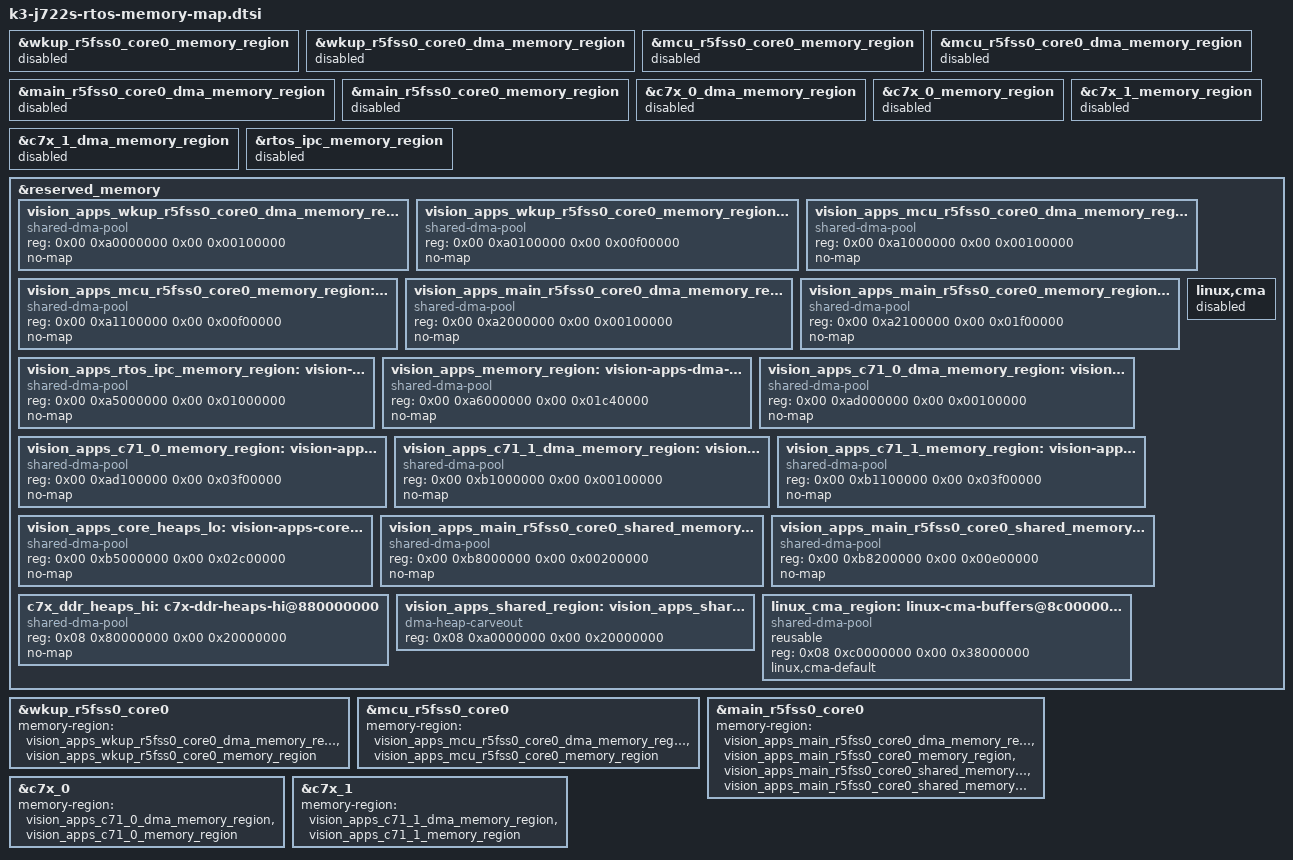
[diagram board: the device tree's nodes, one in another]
// SPDX-License-Identifier: GPL-2.0
/*
 * Vision-apps: device-tree overlay
 *
 * Copyright (C) 2019 Texas Instruments Incorporated - http://www.ti.com/
 */

#include <dt-bindings/soc/ti,sci_pm_domain.h>

&wkup_r5fss0_core0_memory_region {
	status = "disabled";
};

&wkup_r5fss0_core0_dma_memory_region {
	status = "disabled";
};

&mcu_r5fss0_core0_memory_region {
	status = "disabled";
};

&mcu_r5fss0_core0_dma_memory_region {
	status = "disabled";
};

&main_r5fss0_core0_dma_memory_region {
	status = "disabled";
};

&main_r5fss0_core0_memory_region {
	status = "disabled";
};

&c7x_0_dma_memory_region {
	status = "disabled";
};

&c7x_0_memory_region {
	status = "disabled";
};

&c7x_1_dma_memory_region {
	status = "disabled";
};

&c7x_1_memory_region {
	status = "disabled";
};

&rtos_ipc_memory_region {
	status = "disabled";
};

&reserved_memory {
	#address-cells = <2>;
	#size-cells = <2>;

	vision_apps_wkup_r5fss0_core0_dma_memory_region: vision-apps-r5f-dma-memory@a0000000 {
		compatible = "shared-dma-pool";
		reg = <0x00 0xa0000000 0x00 0x00100000>;
		no-map;
	};
	vision_apps_wkup_r5fss0_core0_memory_region: vision-apps-r5f-memory@a0100000 {
		compatible = "shared-dma-pool";
		reg = <0x00 0xa0100000 0x00 0x00f00000>;
		no-map;
	};
	vision_apps_mcu_r5fss0_core0_dma_memory_region: vision-apps-r5f-dma-memory@a1000000 {
		compatible = "shared-dma-pool";
		reg = <0x00 0xa1000000 0x00 0x00100000>;
		no-map;
	};
	vision_apps_mcu_r5fss0_core0_memory_region: vision-apps-r5f-memory@a1100000 {
		compatible = "shared-dma-pool";
		reg = <0x00 0xa1100000 0x00 0x00f00000>;
		no-map;
	};
	vision_apps_main_r5fss0_core0_dma_memory_region: vision-apps-r5f-dma-memory@a2000000 {
		compatible = "shared-dma-pool";
		reg = <0x00 0xa2000000 0x00 0x00100000>;
		no-map;
	};
	vision_apps_main_r5fss0_core0_memory_region: vision-apps-r5f-memory@a2100000 {
		compatible = "shared-dma-pool";
		reg = <0x00 0xa2100000 0x00 0x01f00000>;
		no-map;
	};
	vision_apps_rtos_ipc_memory_region: vision-apps-rtos-ipc-memory-region@a5000000 {
		compatible = "shared-dma-pool";
		reg = <0x00 0xa5000000 0x00 0x01000000>;
		no-map;
	};
	vision_apps_memory_region: vision-apps-dma-memory@a6000000 {
		compatible = "shared-dma-pool";
		reg = <0x00 0xa6000000 0x00 0x01c40000>;
		no-map;
	};
	vision_apps_c71_0_dma_memory_region: vision-apps-c71-dma-memory@ad000000 {
		compatible = "shared-dma-pool";
		reg = <0x00 0xad000000 0x00 0x00100000>;
		no-map;
	};
	vision_apps_c71_0_memory_region: vision-apps-c71_0-memory@ad100000 {
		compatible = "shared-dma-pool";
		reg = <0x00 0xad100000 0x00 0x03f00000>;
		no-map;
	};
	vision_apps_c71_1_dma_memory_region: vision-apps-c71_1-dma-memory@b1000000 {
		compatible = "shared-dma-pool";
		reg = <0x00 0xb1000000 0x00 0x00100000>;
		no-map;
	};
	vision_apps_c71_1_memory_region: vision-apps-c71_1-memory@b1100000 {
		compatible = "shared-dma-pool";
		reg = <0x00 0xb1100000 0x00 0x03f00000>;
		no-map;
	};
	vision_apps_core_heaps_lo: vision-apps-core-heap-memory-lo@b5000000 {
		compatible = "shared-dma-pool";
		reg = <0x00 0xb5000000 0x00 0x02c00000>;
		no-map;
	};
	vision_apps_main_r5fss0_core0_shared_memory_queue_region: vision-apps-r5f-virtual-eth-queues@b8000000 {
		compatible = "shared-dma-pool";
		reg = <0x00 0xb8000000 0x00 0x00200000>;
		no-map;
	};
	vision_apps_main_r5fss0_core0_shared_memory_bufpool_region: vision-apps-r5f-virtual-eth-buffers@b8200000 {
		compatible = "shared-dma-pool";
		reg = <0x00 0xb8200000 0x00 0x00e00000>;
		no-map;
	};
	c7x_ddr_heaps_hi: c7x-ddr-heaps-hi@880000000 {
		compatible = "shared-dma-pool";
		reg = <0x08 0x80000000 0x00 0x20000000>;
		no-map;
	};
	vision_apps_shared_region: vision_apps_shared-memories {
		compatible = "dma-heap-carveout";
		reg = <0x08 0xa0000000 0x00 0x20000000>;
	};
	linux,cma {
		status = "disabled";
	};
	linux_cma_region: linux-cma-buffers@8c0000000 {
		compatible = "shared-dma-pool";
		reusable;
		reg = <0x08 0xc0000000 0x00 0x38000000>;
		linux,cma-default;
	};
};

&wkup_r5fss0_core0 {
	memory-region = <&vision_apps_wkup_r5fss0_core0_dma_memory_region>,
			<&vision_apps_wkup_r5fss0_core0_memory_region>;
};

&mcu_r5fss0_core0 {
	memory-region = <&vision_apps_mcu_r5fss0_core0_dma_memory_region>,
			<&vision_apps_mcu_r5fss0_core0_memory_region>;
};

&main_r5fss0_core0 {
	memory-region = <&vision_apps_main_r5fss0_core0_dma_memory_region>,
			<&vision_apps_main_r5fss0_core0_memory_region>,
			<&vision_apps_main_r5fss0_core0_shared_memory_queue_region>,
			<&vision_apps_main_r5fss0_core0_shared_memory_bufpool_region>;
};

&c7x_0 {
	memory-region = <&vision_apps_c71_0_dma_memory_region>,
			<&vision_apps_c71_0_memory_region>;
};

&c7x_1 {
	memory-region = <&vision_apps_c71_1_dma_memory_region>,
			<&vision_apps_c71_1_memory_region>;
	status = "okay";
};
